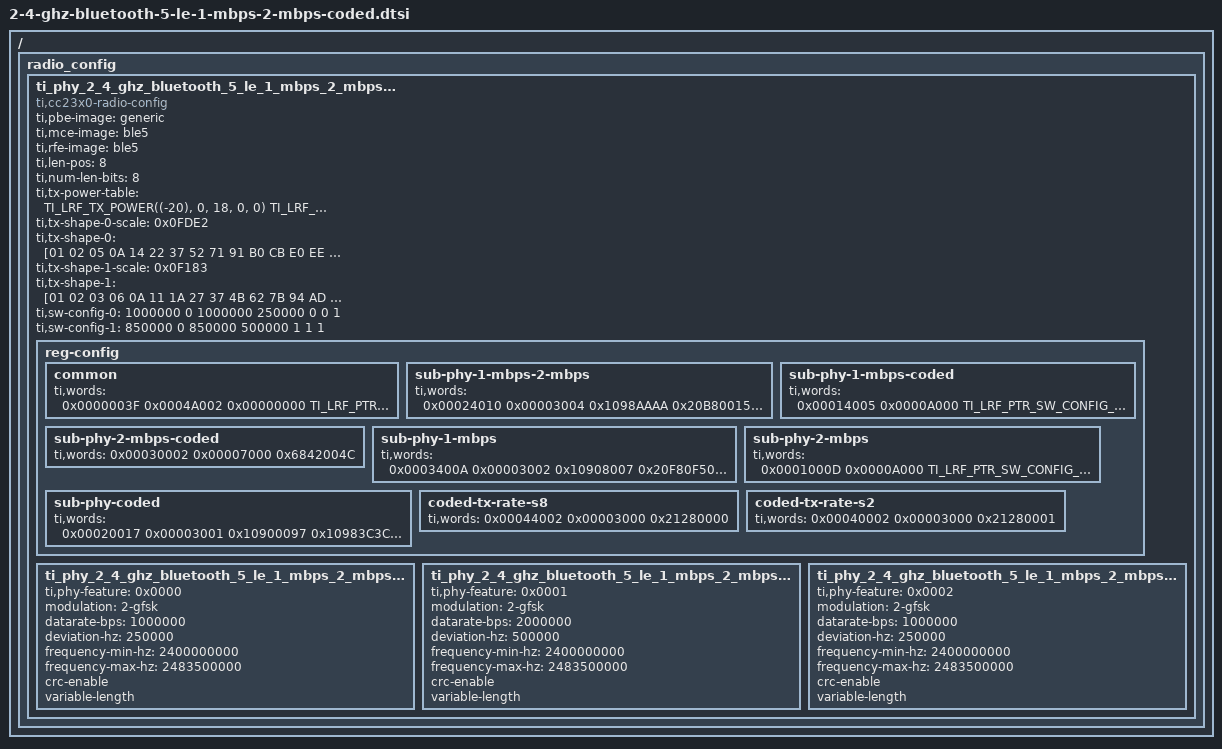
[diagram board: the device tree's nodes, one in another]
/*
 * Copyright (c) 2026 Texas Instruments Incorporated
 * SPDX-License-Identifier: Apache-2.0
 *
 * GENERATED FILE - DO NOT EDIT. Regenerate from SmartRF Studio instead.
 *   PHY name:            2.4 GHz - Bluetooth 5, LE - 1 Mbps / 2 Mbps / Coded
 *   PHY abbreviation/ID: 2_4_ghz_bluetooth_5_le_1_mbps_2_mbps_coded
 *   Device:              CC2340R5
 *   RadioConfig version: 1.4.0.97
 *
 * Usage: include this file from an overlay and reference one of the
 * operating mode nodes below from a ti,cc23x0-prop-rf-phy child:
 *   ti,radio-mode = <&ti_phy_2_4_ghz_bluetooth_5_le_1_mbps_2_mbps_coded_1_mbps>;
 */

#include <dt-bindings/basic_radio/ti-cc23x0-radio-config.h>

/ {
	radio_config {
		ti_phy_2_4_ghz_bluetooth_5_le_1_mbps_2_mbps_coded: 2-4-ghz-bluetooth-5-le-1-mbps-2-mbps-coded {
			compatible = "ti,cc23x0-radio-config";

			/* Microcode images (rf_patches/lrf_<core>_binary_<name>.h) */
			ti,pbe-image = "generic";
			ti,mce-image = "ble5";
			ti,rfe-image = "ble5";

			/* PBE_GENERIC_RAM.LENCFG: length field position and size */
			ti,len-pos = <8>;
			ti,num-len-bits = <8>;

			/* LRF_txPowerTable: TI_LRF_TX_POWER(dBm, tempCoeff, ib, gain, mode) */
			ti,tx-power-table = <TI_LRF_TX_POWER((-20), 0, 18, 0, 0)
					     TI_LRF_TX_POWER((-16), 0, 25, 0, 0)
					     TI_LRF_TX_POWER((-12), 5, 29, 1, 0)
					     TI_LRF_TX_POWER((-8), 18, 44, 1, 0)
					     TI_LRF_TX_POWER((-4), 28, 40, 3, 0)
					     TI_LRF_TX_POWER(0, 40, 21, 6, 0)
					     TI_LRF_TX_POWER(1, 65, 30, 6, 0)
					     TI_LRF_TX_POWER(2, 41, 39, 4, 1)
					     TI_LRF_TX_POWER(3, 43, 31, 5, 1)
					     TI_LRF_TX_POWER(4, 50, 37, 5, 1)
					     TI_LRF_TX_POWER(5, 55, 27, 6, 1)
					     TI_LRF_TX_POWER(6, 75, 38, 6, 1)
					     TI_LRF_TX_POWER(7, 80, 25, 7, 1)
					     TI_LRF_TX_POWER(8, 180, 63, 7, 1)>;

			/* LRF_shapeBaseGfsk067 */
			ti,tx-shape-0-scale = <0x0FDE2>;
			ti,tx-shape-0 = [01 02 05 0A 14 22 37 52 71 91 B0 CB E0 EE F8 FD FF];

			/* LRF_shapeBaseGfsk05 */
			ti,tx-shape-1-scale = <0x0F183>;
			ti,tx-shape-1 = [01 02 03 06 0A 11 1A 27 37 4B 62 7B 94 AD C4 D8 E7 F3 FB FF];

			/* LRF_swConfig1Mbps: rxIntFrequency rxFrequencyOffset txFrequencyOffset
			 * modFrequencyDeviation txShape bwIndex bwIndexDither
			 */
			ti,sw-config-0 = <1000000 0 1000000 250000 0 0 1>;

			/* LRF_swConfig2Mbps: rxIntFrequency rxFrequencyOffset txFrequencyOffset
			 * modFrequencyDeviation txShape bwIndex bwIndexDither
			 */
			ti,sw-config-1 = <850000 0 850000 500000 1 1 1>;

			/* LRF register configuration list, applied in this order */
			reg-config {
				/* Common (LRF_commonRegConfig); modes: 1-mbps, 2-mbps, coded */
				common {
					ti,words = <
						0x0000003F                 /* segment: base (all modes), 63 words */
						0x0004A002                 /* Data structure 32-bit region (start byte position = 4, count = 3) */
						0x00000000                 /* LRF_swParam : txPowerLimitTable */
						TI_LRF_PTR_TX_POWER_TABLE  /* LRF_swParam : txPowerTable */
						TI_LRF_PTR_FCFG_TRIMS      /* LRF_swParam : trimDef */
						0x0000300A                 /* HW sparse region (address/value pairs, count = 11) */
						0x10940000                 /* LRFDPBE.MDMCMDPAR1 */
						0x20C00003                 /* LRFDMDM.ADCDIGCONF */
						0x20C8001F                 /* LRFDMDM.MODSYMMAP0 */
						0x20E40001                 /* LRFDMDM.DEMMISC1 */
						0x20F00000                 /* LRFDMDM.DEMIQMC0 */
						0x20FC0000                 /* LRFDMDM.DEMFIDC0 */
						0x30800000                 /* LRFDRFE.MAGNTHRCFG */
						0x30880000                 /* LRFDRFE.RSSIOFFSET */
						0x30A80000                 /* LRFDRFE.SPARE4 */
						0x31201820                 /* LRFDRFE.MISC0 */
						0x31300C07                 /* LRFDRFE.PHEDISC */
						0x14502004                 /* HW 32-bit region (start address = 0x1450, count = 5) */
						0x22000000                 /* LRFDPBE.POLY0H                      LRFDPBE.POLY0L */
						0x00065B00                 /* LRFDPBE.POLY1H                      LRFDPBE.POLY1L */
						0x00210000                 /* LRFDPBE.FCFG0                       LRFDPBE.PHACFG */
						0x008600C4                 /* LRFDPBE.FCFG2                       LRFDPBE.FCFG1 */
						0x00440080                 /* LRFDPBE.FCFG4                       LRFDPBE.FCFG3 */
						0x14682000                 /* HW 32-bit region (start address = 0x1468, count = 1) */
						0x00020004                 /* LRFDPBE.TXFWBTHRS                   LRFDPBE.RXFRBTHRS */
						0x10DC1001                 /* HW 16-bit region (start address = 0x10DC, count = 2) */
						0x0B0B0202                 /* LRFDPBE.TIMPRE                      LRFDPBE.TIMCTL */
						0x246C2000                 /* HW 32-bit region (start address = 0x246C, count = 1) */
						0x0000000C                 /* LRFDMDM.MODMAIN                     LRFDMDM.BAUDPRE */
						0x30B41001                 /* HW 16-bit region (start address = 0x30B4, count = 2) */
						0x00000006                 /* LRFDRFE.PA0                         LRFDRFE.IFAMPRFLDO */
						0x30C40005                 /* HW zero region (start address = 0x30C4, count = 6) */
						0x30E4100C                 /* HW 16-bit region (start address = 0x30E4, count = 13) */
						0x00000200                 /* LRFDRFE.DCO                         LRFDRFE.ATSTREFH */
						0x00000008                 /* LRFDRFE.DIVLDO                      LRFDRFE.DIV */
						0x00000000                 /* LRFDRFE.DCOLDO0                     LRFDRFE.TDCLDO */
						0x07060000                 /* LRFDRFE.PRE0                        LRFDRFE.DCOLDO1 */
						0x06050000                 /* LRFDRFE.PRE2                        LRFDRFE.PRE1 */
						0x40080603                 /* LRFDRFE.CAL0                        LRFDRFE.PRE3 */
						0x00007F00                 /* -                                   LRFDRFE.CAL1 */
						0x31381002                 /* HW 16-bit region (start address = 0x3138, count = 3) */
						0x047FDF7F                 /* LRFDRFE.PLLMON1                     LRFDRFE.PLLMON0 */
						0x00001804                 /* -                                   LRFDRFE.MOD0 */
						0x2022500A                 /* RAM 16-bit region (start address = 0x2022, count = 11) */
						0x009000B4                 /* PBE_GENERIC_RAM.PKTCFG              PBE_GENERIC_RAM.SYNTHCALTIMEOUT */
						0x03B00018                 /* PBE_GENERIC_RAM.FIFOCFG             PBE_GENERIC_RAM.NUMCRCBITS */
						0x00510000                 /* PBE_GENERIC_RAM.WHITEINIT           PBE_GENERIC_RAM.EXTRABYTES */
						0x55000000                 /* PBE_GENERIC_RAM.CRCINITL            < GAP > */
						0x01085555                 /* PBE_GENERIC_RAM.LENCFG              PBE_GENERIC_RAM.CRCINITH */
						0x00000000                 /* -                                   PBE_GENERIC_RAM.LENOFFSET */
						0x68046005                 /* RAM 32-bit region (start address = 0x6804, count = 6) */
						0x03000012                 /* RFE_COMMON_RAM.TDCCAL0              RFE_COMMON_RAM.SYNTHCTL */
						0x00100000                 /* RFE_COMMON_RAM.TDCCAL2              RFE_COMMON_RAM.TDCCAL1 */
						0x569B0400                 /* RFE_COMMON_RAM.K1LSB                RFE_COMMON_RAM.TDCPLL */
						0x012D010A                 /* RFE_COMMON_RAM.K2BL                 RFE_COMMON_RAM.K1MSB */
						0x132C0034                 /* RFE_COMMON_RAM.K3BL                 RFE_COMMON_RAM.K2AL */
						0x916F07AB                 /* RFE_COMMON_RAM.K5                   RFE_COMMON_RAM.K3AL */
						0x68206005                 /* RAM 32-bit region (start address = 0x6820, count = 6) */
						0x00000000                 /* RFE_COMMON_RAM.RTRIMMIN             RFE_COMMON_RAM.RTRIMOFF */
						0x48080008                 /* RFE_COMMON_RAM.DIVF                 RFE_COMMON_RAM.DIVI */
						0x00000000                 /* RFE_COMMON_RAM.DIVLDOF              RFE_COMMON_RAM.DIVLDOI */
						0x00470014                 /* RFE_COMMON_RAM.LDOSETTLE            RFE_COMMON_RAM.DIVLDOIOFF */
						0x0005002E                 /* RFE_COMMON_RAM.DCOSETTLE            RFE_COMMON_RAM.CHRGSETTLE */
						0x0000FE00                 /* RFE_COMMON_RAM.IFAMPRFLDODEFAULT    RFE_COMMON_RAM.IFAMPRFLDOTX */
					>;
				};
				/* Sub-PHY = 1 Mbps, 2 Mbps (LRF_subPhy1Mbps2MbpsRegConfig); modes: 1-mbps, 2-mbps */
				sub-phy-1-mbps-2-mbps {
					ti,words = <
						0x00024010                 /* segment: phyFeatures bits 0x0002 clear, 16 words */
						0x00003004                 /* HW sparse region (address/value pairs, count = 5) */
						0x1098AAAA                 /* LRFDPBE.MDMCMDPAR2 */
						0x20B80015                 /* LRFDMDM.SYSTIMEVTMUX0 */
						0x20F48087                 /* LRFDMDM.DEMDSBU */
						0x2134005F                 /* LRFDMDM.DEMSWQU0 */
						0x30A41F40                 /* LRFDRFE.SPARE3 */
						0x21001008                 /* HW 16-bit region (start address = 0x2100, count = 9) */
						0x00040224                 /* LRFDMDM.DEMDSXB0                    LRFDMDM.DEMFEXB0 */
						0x04000005                 /* LRFDMDM.DEMMAFI0                    LRFDMDM.DEMFIFE0 */
						0x00C17B20                 /* LRFDMDM.DEMMAFI2                    LRFDMDM.DEMMAFI1 */
						0x7F27000F                 /* LRFDMDM.DEMC1BE1                    LRFDMDM.DEMC1BE0 */
						0x0000017F                 /* -                                   LRFDMDM.DEMC1BE2 */
						0x30B0B000                 /* HW masked region (mask/value pairs, count = 1) */
						0xFF0F000A                 /* LRFDRFE.LNA */
						0x68465001                 /* RAM 16-bit region (start address = 0x6846, count = 2) */
						0x00000045                 /* RFE_COMMON_RAM.AGCINFO              RFE_COMMON_RAM.SPARE1SHADOW */
					>;
				};
				/* Sub-PHY = 1 Mbps, Coded (LRF_subPhy1MbpsCodedRegConfig); modes: 1-mbps, coded */
				sub-phy-1-mbps-coded {
					ti,words = <
						0x00014005                 /* segment: phyFeatures bits 0x0001 clear, 5 words */
						0x0000A000                 /* Data structure 32-bit region (start byte position = 0, count = 1) */
						TI_LRF_PTR_SW_CONFIG_0     /* LRF_swParam : swConfig */
						0x00003001                 /* HW sparse region (address/value pairs, count = 2) */
						0x20D44000                 /* LRFDMDM.BAUD */
						0x21240A18                 /* LRFDMDM.SPARE0 */
					>;
				};
				/* Sub-PHY = 2 Mbps, Coded (LRF_subPhy2MbpsCodedRegConfig); modes: 2-mbps, coded */
				sub-phy-2-mbps-coded {
					ti,words = <
						0x00030002                 /* segment: phyFeatures bits 0x0003 set, 2 words */
						0x00007000                 /* RAM sparse region (address/value pairs, count = 1) */
						0x6842004C                 /* RFE_COMMON_RAM.PHYRSSIOFFSET */
					>;
				};
				/* Sub-PHY = 1 Mbps (LRF_subPhy1MbpsRegConfig); modes: 1-mbps */
				sub-phy-1-mbps {
					ti,words = <
						0x0003400A                 /* segment: phyFeatures bits 0x0003 clear, 10 words */
						0x00003002                 /* HW sparse region (address/value pairs, count = 3) */
						0x10908007                 /* LRFDPBE.MDMCMDPAR0 */
						0x20F80F50                 /* LRFDMDM.DEMCODC0 */
						0x30A0A246                 /* LRFDRFE.SPARE2 */
						0x24742000                 /* HW 32-bit region (start address = 0x2474, count = 1) */
						0x118205F9                 /* LRFDMDM.DEMMISC3                    LRFDMDM.DEMMISC2 */
						0x00007000                 /* RAM sparse region (address/value pairs, count = 1) */
						0x20200000                 /* PBE_GENERIC_RAM.PHY */
						0x68425001                 /* RAM 16-bit region (start address = 0x6842, count = 2) */
						0x75F80050                 /* RFE_COMMON_RAM.SPARE0SHADOW         RFE_COMMON_RAM.PHYRSSIOFFSET */
					>;
				};
				/* Sub-PHY = 2 Mbps (LRF_subPhy2MbpsRegConfig); modes: 2-mbps */
				sub-phy-2-mbps {
					ti,words = <
						0x0001000D                 /* segment: phyFeatures bits 0x0001 set, 13 words */
						0x0000A000                 /* Data structure 32-bit region (start byte position = 0, count = 1) */
						TI_LRF_PTR_SW_CONFIG_1     /* LRF_swParam : swConfig */
						0x00003004                 /* HW sparse region (address/value pairs, count = 5) */
						0x1090800F                 /* LRFDPBE.MDMCMDPAR0 */
						0x20D48000                 /* LRFDMDM.BAUD */
						0x20F80F70                 /* LRFDMDM.DEMCODC0 */
						0x21240A2C                 /* LRFDMDM.SPARE0 */
						0x30A0A357                 /* LRFDRFE.SPARE2 */
						0x24742000                 /* HW 32-bit region (start address = 0x2474, count = 1) */
						0x108100F9                 /* LRFDMDM.DEMMISC3                    LRFDMDM.DEMMISC2 */
						0x00007001                 /* RAM sparse region (address/value pairs, count = 2) */
						0x20200009                 /* PBE_GENERIC_RAM.PHY */
						0x684455FA                 /* RFE_COMMON_RAM.SPARE0SHADOW */
					>;
				};
				/* Sub-PHY = Coded (LRF_subPhyCodedRegConfig); modes: coded */
				sub-phy-coded {
					ti,words = <
						0x00020017                 /* segment: phyFeatures bits 0x0002 set, 23 words */
						0x00003001                 /* HW sparse region (address/value pairs, count = 2) */
						0x10900097                 /* LRFDPBE.MDMCMDPAR0 */
						0x10983C3C                 /* LRFDPBE.MDMCMDPAR2 */
						0x24742000                 /* HW 32-bit region (start address = 0x2474, count = 1) */
						0x158210F9                 /* LRFDMDM.DEMMISC3                    LRFDMDM.DEMMISC2 */
						0x20F41001                 /* HW 16-bit region (start address = 0x20F4, count = 2) */
						0x06F0808D                 /* LRFDMDM.DEMCODC0                    LRFDMDM.DEMDSBU */
						0x21001008                 /* HW 16-bit region (start address = 0x2100, count = 9) */
						0x00060A24                 /* LRFDMDM.DEMDSXB0                    LRFDMDM.DEMFEXB0 */
						0x0000000C                 /* LRFDMDM.DEMMAFI0                    LRFDMDM.DEMFIFE0 */
						0x00783C14                 /* LRFDMDM.DEMMAFI2                    LRFDMDM.DEMMAFI1 */
						0x7F7F001F                 /* LRFDMDM.DEMC1BE1                    LRFDMDM.DEMC1BE0 */
						0x0000014C                 /* -                                   LRFDMDM.DEMC1BE2 */
						0x30941001                 /* HW 16-bit region (start address = 0x3094, count = 2) */
						0x34F21307                 /* LRFDRFE.SPARE0                      LRFDRFE.MAGNCTL1 */
						0x34502000                 /* HW 32-bit region (start address = 0x3450, count = 1) */
						0x00B00013                 /* LRFDRFE.SPARE3                      LRFDRFE.SPARE2 */
						0x30B0B000                 /* HW masked region (mask/value pairs, count = 1) */
						0xFF0F000E                 /* LRFDRFE.LNA */
						0x00007000                 /* RAM sparse region (address/value pairs, count = 1) */
						0x2020001B                 /* PBE_GENERIC_RAM.PHY */
						0x68465001                 /* RAM 16-bit region (start address = 0x6846, count = 2) */
						0x0001001C                 /* RFE_COMMON_RAM.AGCINFO              RFE_COMMON_RAM.SPARE1SHADOW */
					>;
				};
				/* Coded TX rate = S8 (LRF_codedTxRateS8RegConfig); modes: 1-mbps, 2-mbps, coded */
				coded-tx-rate-s8 {
					ti,words = <
						0x00044002                 /* segment: phyFeatures bits 0x0004 clear, 2 words */
						0x00003000                 /* HW sparse region (address/value pairs, count = 1) */
						0x21280000                 /* LRFDMDM.SPARE1 */
					>;
				};
				/* Coded TX rate = S2 (LRF_codedTxRateS2RegConfig); modes: none */
				coded-tx-rate-s2 {
					ti,words = <
						0x00040002                 /* segment: phyFeatures bits 0x0004 set, 2 words */
						0x00003000                 /* HW sparse region (address/value pairs, count = 1) */
						0x21280001                 /* LRFDMDM.SPARE1 */
					>;
				};
			};

			/* Operating mode 1-mbps: phyFeatures 0x0000, LRF_swConfig1Mbps, symbol rate 1000000 sps.
			 */
			ti_phy_2_4_ghz_bluetooth_5_le_1_mbps_2_mbps_coded_1_mbps: mode-1-mbps {
				ti,phy-feature = <0x0000>;
				modulation = "2-gfsk";
				datarate-bps = <1000000>;
				deviation-hz = <250000>;
				frequency-min-hz = <2400000000>;
				frequency-max-hz = <2483500000>;
				crc-enable;
				variable-length;
			};

			/* Operating mode 2-mbps: phyFeatures 0x0001, LRF_swConfig2Mbps, symbol rate 2000000 sps.
			 */
			ti_phy_2_4_ghz_bluetooth_5_le_1_mbps_2_mbps_coded_2_mbps: mode-2-mbps {
				ti,phy-feature = <0x0001>;
				modulation = "2-gfsk";
				datarate-bps = <2000000>;
				deviation-hz = <500000>;
				frequency-min-hz = <2400000000>;
				frequency-max-hz = <2483500000>;
				crc-enable;
				variable-length;
			};

			/* Operating mode coded: phyFeatures 0x0002, LRF_swConfig1Mbps, symbol rate 1000000 sps.
			 */
			ti_phy_2_4_ghz_bluetooth_5_le_1_mbps_2_mbps_coded_coded: mode-coded {
				ti,phy-feature = <0x0002>;
				modulation = "2-gfsk";
				datarate-bps = <1000000>;
				deviation-hz = <250000>;
				frequency-min-hz = <2400000000>;
				frequency-max-hz = <2483500000>;
				crc-enable;
				variable-length;
			};
		};
	};
};
